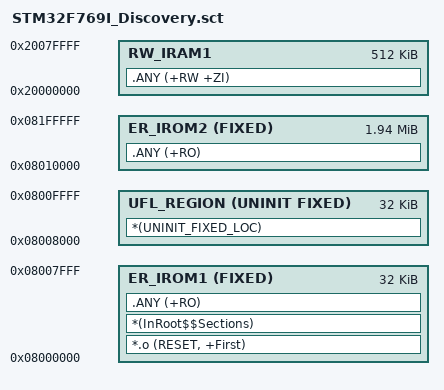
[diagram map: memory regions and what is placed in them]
; *************************************************************
; *** Scatter-Loading Description File generated by uVision ***
; *************************************************************

LR_IROM1 0x08000000 0x00008000  {
  ER_IROM1 0x08000000 FIXED 0x00008000  {
   *.o (RESET, +First)
   *(InRoot$$Sections)
   .ANY (+RO)
  }
}

   

LR_IROM2 0x08008000 0x8000  {
; Definition of the static memory section for the user configuration: TLS certificates, key, and wifi configuration data.
; A whole sector must be reserved so that the linker does not place initialized data there, which 
; would cause a sector erase when the firmware image is programmed.
; This mapping is valid whatever the bank organization:
;    Seen as 1 x 32k sector at 0x08008000 in single bank case
;    Seen as 2 x 16k sectors at 0x08008000 in dual bank case.
  UFL_REGION 0x08008000 UNINIT FIXED 0x8000  {    ; Reserve a chunck for user config.
    *(UNINIT_FIXED_LOC)   
  }
}

LR_IROM3 0x08010000 0x001F0000  {
  ER_IROM2 0x08010000 FIXED 0x001F0000  {
   .ANY (+RO)
  }

  RW_IRAM1 0x20000000 0x00080000  {  ; RW data
   .ANY (+RW +ZI)
  }
}
